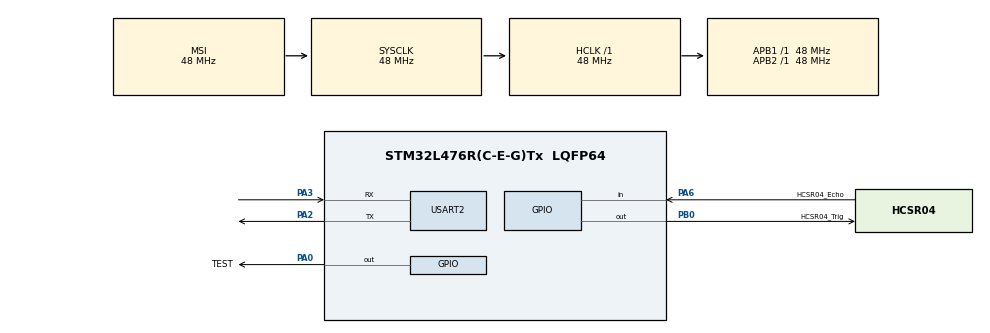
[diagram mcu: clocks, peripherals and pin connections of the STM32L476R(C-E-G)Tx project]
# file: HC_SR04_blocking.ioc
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Mcu.Family=STM32L4
Mcu.Name=STM32L476R(C-E-G)Tx
Mcu.Package=LQFP64
NVIC.PriorityGroup=NVIC_PRIORITYGROUP_4
PA0.GPIO_Label=TEST
PA0.Signal=GPIO_Output
PA2.Mode=Asynchronous
PA2.Signal=USART2_TX
PA3.Mode=Asynchronous
PA3.Signal=USART2_RX
PA6.GPIO_Label=HCSR04_Echo
PA6.Signal=GPIO_Input
PB0.GPIO_Label=HCSR04_Trig
PB0.Signal=GPIO_Output
ProjectManager.HeapSize=0x200
ProjectManager.StackSize=0x400
ProjectManager.TargetToolchain=SW4STM32
RCC.ADCFreq_Value=192000000
RCC.AHBFreq_Value=48000000
RCC.APB1Freq_Value=48000000
RCC.APB1TimFreq_Value=48000000
RCC.APB2Freq_Value=48000000
RCC.APB2TimFreq_Value=48000000
RCC.CortexFreq_Value=48000000
RCC.HCLKFreq_Value=48000000
RCC.HSE_VALUE=8000000
RCC.HSI_VALUE=16000000
RCC.LSE_VALUE=32768
RCC.MSIClockRange=RCC_MSIRANGE_11
RCC.MSI_VALUE=48000000
RCC.SYSCLKFreq_VALUE=48000000
RCC.USBFreq_Value=192000000
RCC.VCOOutputFreq_Value=384000000
TIM3.Period=65535
TIM3.Prescaler=47
USART2.VirtualMode-Asynchronous=VM_ASYNC
VP_TIM3_VS_ClockSourceINT.Mode=Internal
board=custom

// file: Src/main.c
/* USER CODE BEGIN Header */
/**
  ******************************************************************************
  * @file           : main.c
  * @brief          : Main program body
  ******************************************************************************
  ** This notice applies to any and all portions of this file
  * that are not between comment pairs USER CODE BEGIN and
  * USER CODE END. Other portions of this file, whether
  * inserted by the user or by software development tools
  * are owned by their respective copyright owners.
  *
  * COPYRIGHT(c) 2018 STMicroelectronics
  *
  * Redistribution and use in source and binary forms, with or without modification,
  * are permitted provided that the following conditions are met:
  *   1. Redistributions of source code must retain the above copyright notice,
  *      this list of conditions and the following disclaimer.
  *   2. Redistributions in binary form must reproduce the above copyright notice,
  *      this list of conditions and the following disclaimer in the documentation
  *      and/or other materials provided with the distribution.
  *   3. Neither the name of STMicroelectronics nor the names of its contributors
  *      may be used to endorse or promote products derived from this software
  *      without specific prior written permission.
  *
  * THIS SOFTWARE IS PROVIDED BY THE COPYRIGHT HOLDERS AND CONTRIBUTORS "AS IS"
  * AND ANY EXPRESS OR IMPLIED WARRANTIES, INCLUDING, BUT NOT LIMITED TO, THE
  * IMPLIED WARRANTIES OF MERCHANTABILITY AND FITNESS FOR A PARTICULAR PURPOSE ARE
  * DISCLAIMED. IN NO EVENT SHALL THE COPYRIGHT HOLDER OR CONTRIBUTORS BE LIABLE
  * FOR ANY DIRECT, INDIRECT, INCIDENTAL, SPECIAL, EXEMPLARY, OR CONSEQUENTIAL
  * DAMAGES (INCLUDING, BUT NOT LIMITED TO, PROCUREMENT OF SUBSTITUTE GOODS OR
  * SERVICES; LOSS OF USE, DATA, OR PROFITS; OR BUSINESS INTERRUPTION) HOWEVER
  * CAUSED AND ON ANY THEORY OF LIABILITY, WHETHER IN CONTRACT, STRICT LIABILITY,
  * OR TORT (INCLUDING NEGLIGENCE OR OTHERWISE) ARISING IN ANY WAY OUT OF THE USE
  * OF THIS SOFTWARE, EVEN IF ADVISED OF THE POSSIBILITY OF SUCH DAMAGE.
  *
  ******************************************************************************
  */
/* USER CODE END Header */

#include "main.h"
#include "tim.h"
#include "usart.h"
#include "gpio.h"

/* USER CODE BEGIN Includes */
#include <stdio.h>
#include "hcsr04.h"
/* USER CODE END Includes */

/* USER CODE BEGIN PV */
char buf[30];
uint8_t len;
float Distance;
/* USER CODE END PV */

void SystemClock_Config(void);

int main(void)
{

  /* MCU Configuration--------------------------------------------------------*/

  /* Reset of all peripherals, Initializes the Flash interface and the Systick. */
  HAL_Init();

  /* Configure the system clock */
  SystemClock_Config();

  /* Initialize all configured peripherals */
  MX_GPIO_Init();
  MX_TIM3_Init();
  MX_USART2_UART_Init();
  /* USER CODE BEGIN 2 */
  HCSR04_Init(&htim3);
  /* USER CODE END 2 */

  /* Infinite loop */
  /* USER CODE BEGIN WHILE */
  while (1)
  {
	  HAL_GPIO_WritePin(TEST_GPIO_Port, TEST_Pin, 1);

	  HCSR04_Read(&Distance);

	  HAL_GPIO_WritePin(TEST_GPIO_Port, TEST_Pin, 0);

	  len = sprintf(buf, "Distance: %.2f\n\r", Distance);
	  HAL_UART_Transmit(&huart2, (uint8_t*)buf, len, 20);
    /* USER CODE END WHILE */

    /* USER CODE BEGIN 3 */
	  HAL_Delay(20);
  }
  /* USER CODE END 3 */
}

void SystemClock_Config(void)
{
  RCC_OscInitTypeDef RCC_OscInitStruct = {0};
  RCC_ClkInitTypeDef RCC_ClkInitStruct = {0};
  RCC_PeriphCLKInitTypeDef PeriphClkInit = {0};

  /**Initializes the CPU, AHB and APB busses clocks
  */
  RCC_OscInitStruct.OscillatorType = RCC_OSCILLATORTYPE_MSI;
  RCC_OscInitStruct.MSIState = RCC_MSI_ON;
  RCC_OscInitStruct.MSICalibrationValue = 0;
  RCC_OscInitStruct.MSIClockRange = RCC_MSIRANGE_11;
  RCC_OscInitStruct.PLL.PLLState = RCC_PLL_NONE;
  if (HAL_RCC_OscConfig(&RCC_OscInitStruct) != HAL_OK)
  {
    Error_Handler();
  }
  /**Initializes the CPU, AHB and APB busses clocks
  */
  RCC_ClkInitStruct.ClockType = RCC_CLOCKTYPE_HCLK|RCC_CLOCKTYPE_SYSCLK
                              |RCC_CLOCKTYPE_PCLK1|RCC_CLOCKTYPE_PCLK2;
  RCC_ClkInitStruct.SYSCLKSource = RCC_SYSCLKSOURCE_MSI;
  RCC_ClkInitStruct.AHBCLKDivider = RCC_SYSCLK_DIV1;
  RCC_ClkInitStruct.APB1CLKDivider = RCC_HCLK_DIV1;
  RCC_ClkInitStruct.APB2CLKDivider = RCC_HCLK_DIV1;

  if (HAL_RCC_ClockConfig(&RCC_ClkInitStruct, FLASH_LATENCY_2) != HAL_OK)
  {
    Error_Handler();
  }
  PeriphClkInit.PeriphClockSelection = RCC_PERIPHCLK_USART2;
  PeriphClkInit.Usart2ClockSelection = RCC_USART2CLKSOURCE_PCLK1;
  if (HAL_RCCEx_PeriphCLKConfig(&PeriphClkInit) != HAL_OK)
  {
    Error_Handler();
  }
  /**Configure the main internal regulator output voltage
  */
  if (HAL_PWREx_ControlVoltageScaling(PWR_REGULATOR_VOLTAGE_SCALE1) != HAL_OK)
  {
    Error_Handler();
  }
}

void Error_Handler(void)
{
}

/************************ (C) COPYRIGHT STMicroelectronics *****END OF FILE****/
